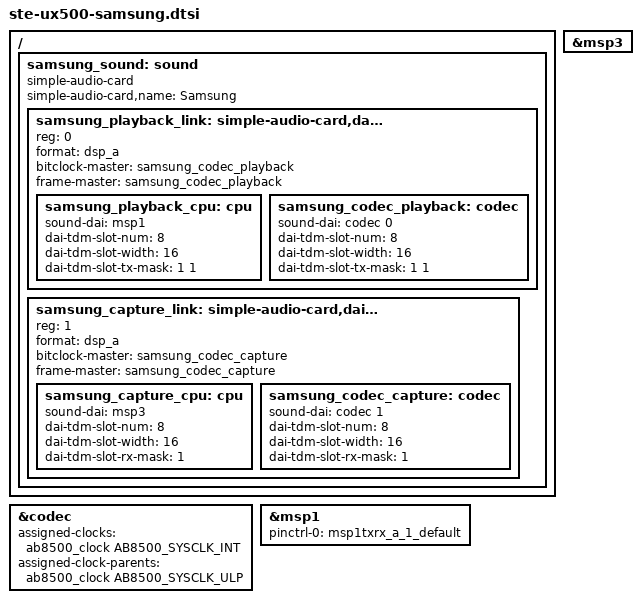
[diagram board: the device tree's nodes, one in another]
// SPDX-License-Identifier: GPL-2.0-only

/ {
	samsung_sound: sound {
		compatible = "simple-audio-card";
		simple-audio-card,name = "Samsung";
		#address-cells = <1>;
		#size-cells = <0>;

		samsung_playback_link: simple-audio-card,dai-link@0 {
			reg = <0>;
			format = "dsp_a";
			bitclock-master = <&samsung_codec_playback>;
			frame-master = <&samsung_codec_playback>;

			samsung_playback_cpu: cpu {
				sound-dai = <&msp1>;
				dai-tdm-slot-num = <8>;
				dai-tdm-slot-width = <16>;
				dai-tdm-slot-tx-mask = <1 1>;
			};

			samsung_codec_playback: codec {
				sound-dai = <&codec 0>;
				dai-tdm-slot-num = <8>;
				dai-tdm-slot-width = <16>;
				dai-tdm-slot-tx-mask = <1 1>;
			};
		};

		samsung_capture_link: simple-audio-card,dai-link@1 {
			reg = <1>;
			format = "dsp_a";
			bitclock-master = <&samsung_codec_capture>;
			frame-master = <&samsung_codec_capture>;

			samsung_capture_cpu: cpu {
				sound-dai = <&msp3>;
				dai-tdm-slot-num = <8>;
				dai-tdm-slot-width = <16>;
				dai-tdm-slot-rx-mask = <1>;
			};

			samsung_codec_capture: codec {
				sound-dai = <&codec 1>;
				dai-tdm-slot-num = <8>;
				dai-tdm-slot-width = <16>;
				dai-tdm-slot-rx-mask = <1>;
			};
		};
	};
};

&codec {
	assigned-clocks = <&ab8500_clock AB8500_SYSCLK_INT>;
	assigned-clock-parents = <&ab8500_clock AB8500_SYSCLK_ULP>;
};

&msp1 {
	pinctrl-names = "default";
	pinctrl-0 = <&msp1txrx_a_1_default>;
	status = "okay";
};

&msp3 {
	status = "okay";
};
